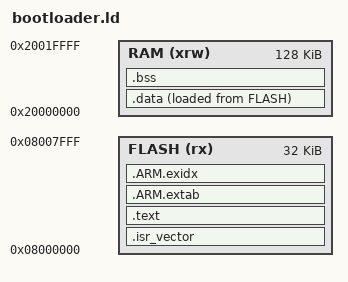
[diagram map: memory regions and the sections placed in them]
/* Bootloader linker script - STM32F446RE (512KB Flash, 128KB SRAM)
 * Bootloader occupies first 32KB of Flash.
 */

ENTRY(Reset_Handler)

MEMORY
{
  FLASH (rx)  : ORIGIN = 0x08000000, LENGTH = 32K
  RAM   (xrw) : ORIGIN = 0x20000000, LENGTH = 128K
}

/* Top of stack */
_estack = ORIGIN(RAM) + LENGTH(RAM);

SECTIONS
{
  .isr_vector :
  {
    KEEP(*(.isr_vector))
  } > FLASH

  .text :
  {
    *(.text*)
    *(.rodata*)
    KEEP(*(.init))
    KEEP(*(.fini))
  } > FLASH

  .ARM.extab : { *(.ARM.extab* .gnu.linkonce.armextab.*) } > FLASH
  .ARM.exidx : { *(.ARM.exidx* .gnu.linkonce.armexidx.*) } > FLASH

  _sidata = LOADADDR(.data);
  .data :
  {
    _sdata = .;
    *(.data*)
    _edata = .;
  } > RAM AT > FLASH

  .bss :
  {
    _sbss = .;
    *(.bss*)
    *(COMMON)
    _ebss = .;
  } > RAM
}
